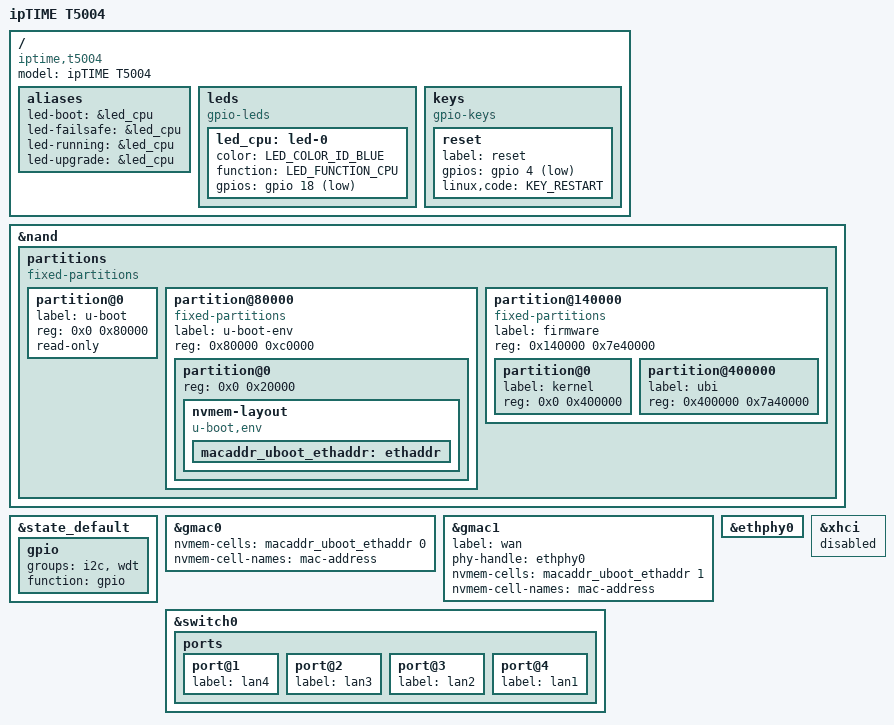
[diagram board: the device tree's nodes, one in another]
// SPDX-License-Identifier: GPL-2.0-or-later OR MIT

#include "mt7621.dtsi"

#include <dt-bindings/gpio/gpio.h>
#include <dt-bindings/input/input.h>
#include <dt-bindings/leds/common.h>

/ {
	compatible = "iptime,t5004", "mediatek,mt7621-soc";
	model = "ipTIME T5004";

	aliases {
		led-boot = &led_cpu;
		led-failsafe = &led_cpu;
		led-running = &led_cpu;
		led-upgrade = &led_cpu;
	};

	leds {
		compatible = "gpio-leds";

		led_cpu: led-0 {
			color = <LED_COLOR_ID_BLUE>;
			function = LED_FUNCTION_CPU;
			gpios = <&gpio 18 GPIO_ACTIVE_LOW>;
		};
	};

	keys {
		compatible = "gpio-keys";

		reset {
			label = "reset";
			gpios = <&gpio 4 GPIO_ACTIVE_LOW>;
			linux,code = <KEY_RESTART>;
		};
	};
};

&nand {
	status = "okay";

	partitions {
		compatible = "fixed-partitions";
		#address-cells = <1>;
		#size-cells = <1>;

		partition@0 {
			label = "u-boot";
			reg = <0x0 0x80000>;
			read-only;
		};

		partition@80000 {
			label = "u-boot-env";
			reg = <0x80000 0xc0000>;

			compatible = "fixed-partitions";
			#address-cells = <1>;
			#size-cells = <1>;

			partition@0 {
				reg = <0x0 0x20000>;

				nvmem-layout {
					compatible = "u-boot,env";
					#address-cells = <1>;
					#size-cells = <1>;

					macaddr_uboot_ethaddr: ethaddr {
						#nvmem-cell-cells = <1>;
					};
				};
			};
		};

		partition@140000 {
			label = "firmware";
			reg = <0x140000 0x7e40000>;

			compatible = "fixed-partitions";
			#address-cells = <1>;
			#size-cells = <1>;

			partition@0 {
				label = "kernel";
				reg = <0x0 0x400000>;
			};

			partition@400000 {
				label = "ubi";
				reg = <0x400000 0x7a40000>;
			};
		};
	};
};

&state_default {
	gpio {
		groups = "i2c", "wdt";
		function = "gpio";
	};
};

&gmac0 {
	nvmem-cells = <&macaddr_uboot_ethaddr 0>;
	nvmem-cell-names = "mac-address";
};

&gmac1 {
	status = "okay";
	label = "wan";
	phy-handle = <&ethphy0>;

	nvmem-cells = <&macaddr_uboot_ethaddr 1>;
	nvmem-cell-names = "mac-address";
};

&ethphy0 {
	/delete-property/ interrupts;
};

&switch0 {
	ports {
		port@1 {
			status = "okay";
			label = "lan4";
		};

		port@2 {
			status = "okay";
			label = "lan3";
		};

		port@3 {
			status = "okay";
			label = "lan2";
		};

		port@4 {
			status = "okay";
			label = "lan1";
		};
	};
};

&xhci {
	status = "disabled";
};
